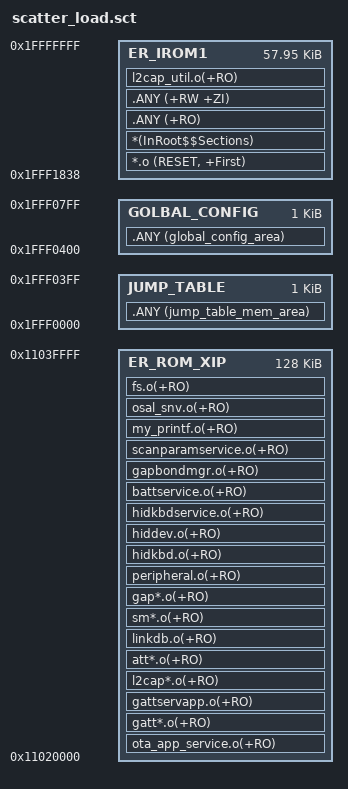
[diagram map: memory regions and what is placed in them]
; *************************************************************
; *** Scatter-Loading Description File generated by uVision ***
; *************************************************************

 LR_IROM1 0x1fff1838 0x000E7C8 {  ; load region size_region
  ER_IROM1 0x1fff1838 0x000E7C8  {  ; load address = execution address
   *.o (RESET, +First)
   *(InRoot$$Sections)
   .ANY (+RO)  
   .ANY (+RW +ZI)
   l2cap_util.o(+RO)
  }
  
 }
 
LR_ROM_JT_GC  0x1fff0000 0x00800 {
  JUMP_TABLE 0x1fff0000 0x00400  {
   .ANY (jump_table_mem_area) 
	
  }
  GOLBAL_CONFIG 0x1fff0400 0x00400  {
   .ANY (global_config_area) 
	
  }  
 } 
;LR_IROM5  0x1fffc000 0x04000 {
;  ER_IROM5 0x1fffc000 0x04000  {
;   rf_phy_driver.o(i.rf_phy_direct_test)
;  }
; } 

LR_ROM_XIP  0x11020000 0x020000 {
  ER_ROM_XIP 0x11020000 0x020000  {  ; load address = execution address
   ;libethermind_mesh_models.o(+RO) 
   ;libethermind_utils.o(+RO) 
   ;libethermind_mesh_core.o(+RO) 
   ;appl_*.o(+RO)
   ;;;;;
   ;devinfoservice.o(+RO)
   ota_app_service.o(+RO)
   gatt*.o(+RO)
   gattservapp.o(+RO)
   l2cap*.o(+RO)
   att*.o(+RO)
   linkdb.o(+RO)
   sm*.o(+RO)
   gap*.o(+RO)
   peripheral.o(+RO)
   hidkbd.o(+RO)
   hiddev.o(+RO)
   hidkbdservice.o(+RO)
   battservice.o(+RO)
   gapbondmgr.o(+RO)
   scanparamservice.o(+RO)
   my_printf.o(+RO)
   osal_snv.o(+RO)
   fs.o(+RO)
  }
 }  



